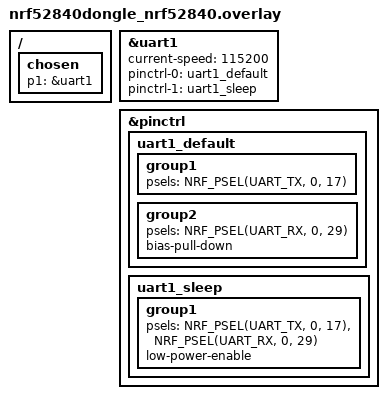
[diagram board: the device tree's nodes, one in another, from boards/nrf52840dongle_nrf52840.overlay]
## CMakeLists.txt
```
# SPDX-License-Identifier: Apache-2.0

cmake_minimum_required(VERSION 3.20.0)

find_package(Zephyr REQUIRED HINTS $ENV{ZEPHYR_BASE})
project(blep1)

SET(CMAKE_C_FLAGS "-O0")
SET(CMAKE_CPP_FLAGS "-O0")
set(CMAKE_BUILD_TYPE Debug)

FILE(GLOB app_sources src/*.c)
target_sources(app PRIVATE
  ${app_sources}
  )
```

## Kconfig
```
mainmenu "Blep1 application"

config BLEP1_SIM_DATA_ENABLED
  bool "Create some simulated data"
  default y

choice BLEP1_DATA_SOURCE
  bool "Choice of data source"
  default BLEP1_UART_DATA_SOURCE

config BLEP1_UART_DATA_SOURCE
  bool "Read data from UART"
  depends on BLEP1_SERIAL

config BLEP1_SIM_DATA_SOURCE
  bool "Read data directly from simulator"
endchoice

config BLEP1_SERIAL
  bool "Receive data from UART"
  default y

config BLEP1_SIM_UART_OUT
  bool "Send dummy data over tx line"
  default y
  depends on BLEP1_UART_DATA_SOURCE

config BLEP_IGNORE_UNKNOWN
  bool "Ignore unknown OBIS fields"
  default y

config BLEP_IGNORE_PARSING_ERRORS
  bool "Ignore fields with parsing errors"
  default y

choice BLEP_SOCKET_TYPE
  bool "Socket type"
  default BLEP_UDP

config BLEP_TCP
  bool "Use TCP socket"
  depends on NET_TCP

config BLEP_UDP
  bool "Use UDP socket"
  depends on NET_UDP
endchoice

config BLEP_HOSTNAME
  string "Hostname"
  default "blep-device"

config BLEP_SRP_INSTANCE_NAME
  string "SRP instance name"
  default "BLEP1 device"

config BLEP_LOG_TCP
  bool "Use TCP server for sending logs"
  default y

source "Kconfig.zephyr"
```

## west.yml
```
manifest:
  remotes:
    - name: zephyrproject-rtos
      url-base: https://github.com/zephyrproject-rtos
  projects:
    - name: zephyr
      remote: zephyrproject-rtos
      revision: v3.3.0
      import:
        path-prefix: external-code
```

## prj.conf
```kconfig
CONFIG_PIPES=y

CONFIG_BLEP_TCP=y

# Generic networking options
CONFIG_NETWORKING=y
CONFIG_NET_UDP=y
CONFIG_NET_TCP=y
CONFIG_NET_IPV6=y
CONFIG_NET_IPV4=n
CONFIG_NET_SOCKETS=y
CONFIG_NET_SOCKETS_POSIX_NAMES=y
CONFIG_POSIX_MAX_FDS=6
CONFIG_NET_CONNECTION_MANAGER=y

# Logging
CONFIG_LOG_MODE_DEFERRED=y
CONFIG_LOG_BUFFER_SIZE=4096
CONFIG_LOG_RUNTIME_FILTERING=y
CONFIG_LOG_FUNC_NAME_PREFIX_WRN=n
CONFIG_LOG_FUNC_NAME_PREFIX_INF=n
CONFIG_LOG_FUNC_NAME_PREFIX_ERR=n
CONFIG_LOG_FUNC_NAME_PREFIX_DBG=n

#CONFIG_FPU_SHARING=y

#CONFIG_BT_DEBUG_HCI_CORE=y

CONFIG_MODBUS=y
CONFIG_MODBUS_ROLE_SERVER=y
CONFIG_MODBUS_RAW_ADU=y
CONFIG_MODBUS_NUMOF_RAW_ADU=1
```

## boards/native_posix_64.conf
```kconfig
CONFIG_OPENP1_SERIAL=n

CONFIG_OPENP1_SIM_DATA_ENABLED=y
CONFIG_OPENP1_SIM_DATA_SOURCE=y

CONFIG_OPENP1_UART_DATA_SOURCE=n
CONFIG_OPENP1_SIM_UART_OUT=n

CONFIG_OPENP1_IGNORE_UNKNOWN=y
CONFIG_OPENP1_IGNORE_PARSING_ERRORS=n

CONFIG_SERIAL=n
CONFIG_UART_CONSOLE=n

CONFIG_NET_BUF=y

# Logging
CONFIG_NET_LOG=y
CONFIG_LOG=y
CONFIG_NET_STATISTICS=y
CONFIG_PRINTK=y

# Generic networking options
CONFIG_NETWORKING=y
CONFIG_NET_UDP=y
CONFIG_NET_IPV6=y
CONFIG_NET_SOCKETS=y
CONFIG_NET_SOCKETS_POSIX_NAMES=y
CONFIG_POSIX_MAX_FDS=6
CONFIG_NET_CONNECTION_MANAGER=y

# Network shell
CONFIG_SHELL=y
CONFIG_NATIVE_UART_0_ON_STDINOUT=y
CONFIG_NET_SHELL=y
CONFIG_NET_TCP=y

CONFIG_NET_CONFIG_SETTINGS=y

CONFIG_NET_CONFIG_MY_IPV6_ADDR="2001:db8:100::1"
CONFIG_NET_CONFIG_PEER_IPV6_ADDR="2001:db8:100::2"
CONFIG_ETH_NATIVE_POSIX_RANDOM_MAC=n
CONFIG_ETH_NATIVE_POSIX_MAC_ADDR="00:00:5e:00:53:64"
CONFIG_ETH_NATIVE_POSIX_STARTUP_AUTOMATIC=y
CONFIG_ETH_NATIVE_POSIX_SETUP_SCRIPT="./posix_net_setup.sh"
CONFIG_ETH_NATIVE_POSIX_DRV_NAME="zeth.1"
```

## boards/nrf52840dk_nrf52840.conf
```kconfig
CONFIG_SERIAL=y
CONFIG_UART_INTERRUPT_DRIVEN=y

CONFIG_NRFX_UARTE1=y
CONFIG_NFCT_PINS_AS_GPIOS=y

CONFIG_FPU=y

CONFIG_OPENP1_HOSTNAME="blep-dk"

# Kernel options
CONFIG_ENTROPY_GENERATOR=y
CONFIG_TEST_RANDOM_GENERATOR=y
CONFIG_INIT_STACKS=y

# Logging
CONFIG_NET_LOG=y
CONFIG_LOG=y
CONFIG_NET_STATISTICS=y
CONFIG_PRINTK=y

# Network buffers
CONFIG_NET_PKT_RX_COUNT=16
CONFIG_NET_PKT_TX_COUNT=16
CONFIG_NET_BUF_RX_COUNT=64
CONFIG_NET_BUF_TX_COUNT=64
CONFIG_NET_CONTEXT_NET_PKT_POOL=y

# IP address options
CONFIG_NET_IF_UNICAST_IPV6_ADDR_COUNT=6
CONFIG_NET_IF_MCAST_IPV6_ADDR_COUNT=4
CONFIG_NET_MAX_CONTEXTS=10

# Network shell
CONFIG_NET_SHELL=y
CONFIG_SHELL=y

# Network application options and configuration
CONFIG_NET_CONFIG_SETTINGS=y
CONFIG_NET_CONFIG_NEED_IPV6=y
#CONFIG_NET_CONFIG_MY_IPV6_ADDR="2001:db8::1"
#CONFIG_NET_CONFIG_PEER_IPV6_ADDR="2001:db8::2"

# How many client can connect to echo-server simultaneously

# These will break openthread! https://github.com/zephyrproject-rtos/zephyr/issues/34597
CONFIG_NET_IPV6_NBR_CACHE=n
CONFIG_NET_IPV6_MLD=n


CONFIG_SYSTEM_WORKQUEUE_STACK_SIZE=4096

# Enable OpenThread shell
CONFIG_OPENTHREAD_SHELL=y
CONFIG_SHELL_STACK_SIZE=3072

CONFIG_NET_L2_OPENTHREAD=y
#CONFIG_NET_IPV6_LOG_LEVEL_DBG=y

#CONFIG_OPENTHREAD_DEBUG=y
#CONFIG_OPENTHREAD_L2_DEBUG=y
#CONFIG_OPENTHREAD_L2_LOG_LEVEL_INF=y
#CONFIG_OPENTHREAD_LOG_LEVEL_INFO=y

CONFIG_OPENTHREAD_SLAAC=y
CONFIG_OPENTHREAD_JOINER=y
CONFIG_OPENTHREAD_JOINER_AUTOSTART=y
CONFIG_OPENTHREAD_JOINER_PSKD="ME0W4U"
CONFIG_OPENTHREAD_MANUAL_START=n
CONFIG_OPENTHREAD_PING_SENDER=y
CONFIG_OPENTHREAD_SRP_CLIENT=y
CONFIG_OPENTHREAD_DIAG=y
CONFIG_OPENTHREAD_RADIO_WORKQUEUE_STACK_SIZE=1024

# mbedTLS tweaks
CONFIG_MBEDTLS_SSL_MAX_CONTENT_LEN=768
CONFIG_MBEDTLS_HEAP_SIZE=16384

CONFIG_MAIN_STACK_SIZE=8192
CONFIG_PICOLIBC=y
```

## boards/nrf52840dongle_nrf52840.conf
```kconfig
CONFIG_SERIAL=y
CONFIG_UART_INTERRUPT_DRIVEN=y

CONFIG_BLEP1_SIM_DATA_ENABLED=n
CONFIG_BLEP1_UART_DATA_SOURCE=y
CONFIG_BLEP1_SIM_UART_OUT=n

CONFIG_NRFX_UARTE1=y
CONFIG_NFCT_PINS_AS_GPIOS=y

#CONFIG_POSIX_API=y
CONFIG_PICOLIBC=y
CONFIG_FPU=y

CONFIG_CONSOLE=y
CONFIG_UART_CONSOLE=y

# Kernel options
CONFIG_ENTROPY_GENERATOR=y
CONFIG_TEST_RANDOM_GENERATOR=y
CONFIG_INIT_STACKS=y

# Logging
CONFIG_NET_LOG=y
CONFIG_LOG=y
CONFIG_NET_STATISTICS=y
CONFIG_PRINTK=y

# Network buffers
CONFIG_NET_PKT_RX_COUNT=16
CONFIG_NET_PKT_TX_COUNT=16
CONFIG_NET_BUF_RX_COUNT=64
CONFIG_NET_BUF_TX_COUNT=64
CONFIG_NET_CONTEXT_NET_PKT_POOL=y

# IP address options
CONFIG_NET_IF_UNICAST_IPV6_ADDR_COUNT=6
CONFIG_NET_IF_MCAST_IPV6_ADDR_COUNT=4
CONFIG_NET_MAX_CONTEXTS=10

# Network shell
CONFIG_NET_SHELL=y
CONFIG_SHELL=y

# Network application options and configuration
CONFIG_NET_CONFIG_SETTINGS=y
CONFIG_NET_CONFIG_NEED_IPV6=y
#CONFIG_NET_CONFIG_MY_IPV6_ADDR="2001:db8::1"
#CONFIG_NET_CONFIG_PEER_IPV6_ADDR="2001:db8::2"

# How many client can connect to echo-server simultaneously

# These will break openthread! https://github.com/zephyrproject-rtos/zephyr/issues/34597
CONFIG_NET_IPV6_NBR_CACHE=n
CONFIG_NET_IPV6_MLD=n


CONFIG_SYSTEM_WORKQUEUE_STACK_SIZE=4096

# Enable OpenThread shell
CONFIG_OPENTHREAD_SHELL=y
CONFIG_SHELL_STACK_SIZE=3072

CONFIG_NET_L2_OPENTHREAD=y
#CONFIG_NET_IPV6_LOG_LEVEL_DBG=y

#CONFIG_OPENTHREAD_DEBUG=y
#CONFIG_OPENTHREAD_L2_DEBUG=y
#CONFIG_OPENTHREAD_L2_LOG_LEVEL_INF=y
#CONFIG_OPENTHREAD_LOG_LEVEL_INFO=y

CONFIG_OPENTHREAD_SLAAC=y
CONFIG_OPENTHREAD_JOINER=y
CONFIG_OPENTHREAD_JOINER_AUTOSTART=y
CONFIG_OPENTHREAD_JOINER_PSKD="ME0W4U"
CONFIG_OPENTHREAD_MANUAL_START=n
CONFIG_OPENTHREAD_PING_SENDER=y
CONFIG_OPENTHREAD_SRP_CLIENT=y
CONFIG_OPENTHREAD_DIAG=y
CONFIG_OPENTHREAD_RADIO_WORKQUEUE_STACK_SIZE=1024

# mbedTLS tweaks
CONFIG_MBEDTLS_SSL_MAX_CONTENT_LEN=768
CONFIG_MBEDTLS_HEAP_SIZE=16384

CONFIG_MAIN_STACK_SIZE=8192
CONFIG_PICOLIBC=y
```

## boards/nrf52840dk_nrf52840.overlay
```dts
/ {
	chosen {
		p1 = &uart1;
	};
};

&uart1 {
	status = "okay";
	current-speed = <115200>;
	pinctrl-0 = <&uart1_default>;
	pinctrl-1 = <&uart1_sleep>;
	pinctrl-names = "default", "sleep";
};

/*
&pinctrl {
	uart1_default: uart1_default {
		group1 {
			psels = <NRF_PSEL(UART_TX, 1, 10)>;
		};
		group2 {
			psels =	<NRF_PSEL(UART_RX, 0, 10)>;
			bias-pull-up;
		};
	};

	uart1_sleep: uart1_sleep {
		group1 {
			psels = <NRF_PSEL(UART_TX, 1, 10)>,
			      	<NRF_PSEL(UART_RX, 0, 10)>;
			low-power-enable;
		};
	};
};
*/
```

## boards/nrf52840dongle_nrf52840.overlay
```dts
/ {
	chosen {
		p1 = &uart1;
	};
};

&uart1 {
	status = "okay";
	current-speed = <115200>;
	pinctrl-0 = <&uart1_default>;
	pinctrl-1 = <&uart1_sleep>;
	pinctrl-names = "default", "sleep";
};

&pinctrl {
	uart1_default: uart1_default {
		group1 {
			psels = <NRF_PSEL(UART_TX, 0, 17)>;
		};
		group2 {
			psels =	<NRF_PSEL(UART_RX, 0, 29)>;
			bias-pull-down;
		};
	};

	uart1_sleep: uart1_sleep {
		group1 {
			psels = <NRF_PSEL(UART_TX, 0, 17)>,
			      	<NRF_PSEL(UART_RX, 0, 29)>;
			low-power-enable;
		};
	};
};
```

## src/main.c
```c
#include "lib/openp1.h"
#include "lib/parser.h"
#include "lib/telegram.h"
#include "lib/value_store.h"

#include "uart_p1.h"
#include "framer_task.h"
#include "parser_task.h"
#include "handler_task.h"
#include "modbus.h"
#include "tcp_log.h"

#include <zephyr/kernel.h>
#include <zephyr/logging/log.h>
#include <zephyr/net/openthread.h>
#include <openthread/srp_client.h>
#include <openthread/instance.h>

K_PIPE_DEFINE(rx_pipe, 4096, 4);
K_PIPE_DEFINE(tx_pipe, 4096, 4);
K_FIFO_DEFINE(telegram_frame_fifo);
K_MSGQ_DEFINE(telegram_queue, sizeof(telegram_message), 1, 4); 

LOG_MODULE_REGISTER(main, LOG_LEVEL_DBG);

const char HOSTNAME[] = CONFIG_OPENP1_HOSTNAME; 

struct value_store value_store;

void update_data_store(struct data_item *data_item) {
	value_store_update(&value_store, data_item);
}

#if CONFIG_OPENTHREAD
//typedef void (*otSrpClientAutoStartCallback)(const otSockAddr *aServerSockAddr, void *aContext);
void on_ot_srp_client_autostart_cb(const otSockAddr *aServerSockAddr, void *aContext) {
	uint8_t buf[INET6_ADDRSTRLEN];
	otIp6AddressToString(&aServerSockAddr->mAddress, buf, INET6_ADDRSTRLEN);
	LOG_INF("SRP autostart callback. Server: %s", buf);
}

const char INSTANCE_NAME[] = CONFIG_OPENP1_SRP_INSTANCE_NAME;
#if CONFIG_OPENP1_UDP
const char SERVICE_LABEL[] = "_blep1-modbus._udp";
#elif CONFIG_OPENP1_TCP
const char SERVICE_LABEL[] = "_blep1-modbus._tcp";
#else
const char SERVICE_LABEL[] = "_blep1-unknown._unknown";
#endif
struct otSrpClientService srp_client_service = {0};

static int service_registration() {
	struct otInstance *otInstance = openthread_get_default_instance();
	if (otInstance == NULL) {
		LOG_ERR("Openthread instance not available");
		return -1;
	}
	int ret = otSrpClientEnableAutoHostAddress(otInstance);
	if (ret != OT_ERROR_NONE) {
		LOG_ERR("Could not set auto host name address, error: %d", ret);
		return -1;
	}
	ret = otSrpClientSetHostName(otInstance, HOSTNAME);
	if (ret != OT_ERROR_NONE) {
		LOG_ERR("Could not set host name address, error: %d", ret);
		return -1;
	}
	srp_client_service.mInstanceName = INSTANCE_NAME;
	srp_client_service.mName = SERVICE_LABEL;
	srp_client_service.mPort = 502;

	ret = otSrpClientAddService(otInstance, &srp_client_service);
	if (ret != OT_ERROR_NONE) {
		LOG_ERR("Could not set service, error: %d", ret);
		return -1;
	}
	otSrpClientEnableAutoStartMode(otInstance, &on_ot_srp_client_autostart_cb, NULL);
	LOG_INF("Service discovery setup done");

	return 0;
}
#else
static int service_registration() { 
	LOG_INF("No service registration configured");
	return 0;
}

#endif


void main(void) {
	int err;
	LOG_INF("Starting..");

#if CONFIG_OPENP1_SERIAL
	err = uart_p1_init(&rx_pipe, &tx_pipe);
	if (err < 0) {
		LOG_ERR("Could not init uart (err %d)", err);
		return;
	}
#endif

	err = framer_task_init(&rx_pipe, &telegram_frame_fifo);
	if (err < 0) {
		LOG_ERR("Could not init parser task (err %d)", err);
		return;
	}

	err = parser_task_init(&telegram_frame_fifo, &telegram_queue);
	if (err < 0) {
		LOG_ERR("Could not init parser task (err %d)", err);
		return;
	}

	err = handler_task_init(&telegram_queue, &update_data_store);
	if (err < 0) {
		LOG_ERR("Could not init handler task (err %d)", err);
		return;
	}

	err = modbus_init(&value_store);
	if (err < 0) {
		LOG_ERR("Could not initalize Modbus server");
		return;
	}

#if CONFIG_OPENP1_LOG_TCP
	err = tcp_log_server_start();
	if (err < 0) {
		LOG_ERR("Could not initalize tcp log server");
		return;
	}
#endif

	err = service_registration();
	if (err < 0) {
		LOG_ERR("Could not start service registration");
		return;
	}

	LOG_INF("Up and running..");

	while (true) {
		k_sleep(K_SECONDS(1));
	}
}
```

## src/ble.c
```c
#include <zephyr/kernel.h>
#include <zephyr/logging/log.h>

#include <zephyr/bluetooth/bluetooth.h>
#include <zephyr/bluetooth/hci.h>
#include <zephyr/bluetooth/conn.h>
#include <zephyr/bluetooth/uuid.h>
#include <zephyr/bluetooth/gatt.h>

#include "ble.h"
#include "nus_log.h"

#include "lib/ble_definitions.h"
#include "lib/blep1.h"
#include "lib/common.h"

#if 0
LOG_MODULE_REGISTER(ble, LOG_LEVEL_DBG);

static struct bt_uuid_16 CHRC_UUID = BT_UUID_INIT_16(BT_UUID_GATT_CHRC_VAL);
static struct bt_uuid_16 CUD_UUID = BT_UUID_INIT_16(BT_UUID_GATT_CUD_VAL);
static struct bt_uuid_16 CPF_UUID = BT_UUID_INIT_16(BT_UUID_GATT_CPF_VAL);
static struct bt_uuid_16 CCC_UUID = BT_UUID_INIT_16(BT_UUID_GATT_CCC_VAL);

static ssize_t read_value(struct bt_conn *conn, const struct bt_gatt_attr *attr,
      void *buf, uint16_t len, uint16_t offset)
{
  struct user_data *user_data = attr->user_data;

  struct data_item data_item = {user_data->item, user_data->value };
  uint16_t size = data_item_size(&data_item);

//  LOG_DBG("Reading item: %d %d", user_data->item, user_data->value);

  return bt_gatt_attr_read(conn, attr, buf, len, offset, &user_data->value, size);
}

#define MAX_ATTRIBUTES 512

int ble_service_add_attributes(struct ble_service *ble_service, struct bt_gatt_attr *attributes, int count) {
	struct bt_gatt_attr *service_attributes = ble_service->gatt_service.attrs;
	size_t *index = &(ble_service->gatt_service.attr_count);

	for (int i = 0 ; i < count ; i++) {
		if (*index >= MAX_ATTRIBUTES) {
			LOG_ERR("Max attributes reached: %d", *index);
			return -1;
		}
		// Copy..
		service_attributes[*index] = attributes[i];
		*index += 1;
	}
	return 0;
}

int ble_service_update_item(struct ble_service *service, struct data_item *data_item) {
	int ret;
	struct user_data *data = &service->user_data[data_item->item];
	data->value = data_item->value;
	data->last_updated = 1;
	ret = bt_gatt_notify(NULL, data->attr, &data->value, data_item_size(data_item));
	if (ret < 0) {
		// This is normal when not connected..
		return -1;
	}
	return 0;
}

const struct bt_gatt_attr primary_service = BT_GATT_PRIMARY_SERVICE(&blep1_uuid);

int ble_service_add_primary_service(struct ble_service *service) {

	struct bt_gatt_attr attributes[] = { 
		primary_service
	};
	int ret = ble_service_add_attributes(service, attributes, ARRAY_SIZE(attributes));
	if (ret < 0) {
		LOG_ERR("Could not add primary service attribute(s)");
		return -1;
	}
	return 0;
}

int ble_service_add_item_attributes(struct ble_service * service) {
	for (int item = 0; item < _ITEM_COUNT; item++) {
		const struct gatt_ch *ch = &gatt_ch_table[item];
		struct bt_gatt_attr attributes[] = {
			BT_GATT_ATTRIBUTE(&CHRC_UUID.uuid, BT_GATT_PERM_READ, bt_gatt_attr_read_chrc, NULL, &service->chrc[item]),
			BT_GATT_ATTRIBUTE(&ch->uuid->uuid, BT_GATT_PERM_READ, read_value, NULL, &service->user_data[item]),
			BT_GATT_ATTRIBUTE(&CUD_UUID.uuid, BT_GATT_PERM_READ, bt_gatt_attr_read_cud, NULL, ch->description),
			BT_GATT_ATTRIBUTE(&CPF_UUID.uuid, BT_GATT_PERM_READ, bt_gatt_attr_read_cpf, NULL, ch->cpf), 
			BT_GATT_ATTRIBUTE(&CCC_UUID.uuid, BT_GATT_PERM_READ | BT_GATT_PERM_WRITE, 
				bt_gatt_attr_read_ccc, bt_gatt_attr_write_ccc, &service->ccc[item])
		};
		int ret = ble_service_add_attributes(service, attributes, ARRAY_SIZE(attributes));
		if (ret < 0) {
			LOG_ERR("Could not add item attribute: %d", item);
			return -1;
		}
		// Add a self reference for notficationas
		// Assumes the value attribute is third from bottom in list above
		struct bt_gatt_attr *value_attr = &service->gatt_service.attrs[service->gatt_service.attr_count - 4];
		service->user_data[item] = (struct user_data) { 
			.item = ch->item, 
			.last_updated = 0, 
			.attr = value_attr, 
		};
	}
	return 0;
}

void ble_service_init_chrc(struct ble_service *service) {
	for(int i = 0 ; i < ARRAY_SIZE(service->chrc); i++) {
		service->chrc[i] = (struct bt_gatt_chrc) { 
			.uuid = &(gatt_ch_table[i].uuid->uuid), 
			.value_handle = 0U, 
			.properties = BT_GATT_CHRC_READ  | BT_GATT_CHRC_NOTIFY,
		};
	}
}

void ble_service_init_ccc(struct ble_service *service) {
	for(int i = 0 ; i < ARRAY_SIZE(service->ccc); i++) {
		service->ccc[i] = (struct _bt_gatt_ccc) { 
			.cfg = {},
			.cfg_changed = NULL,
			.cfg_match = NULL,
			.cfg_write = NULL,
		};
	}
}

int ble_service_init(struct ble_service *service) {
	int err;
	// Allocate storage for max attributes, but uses less, saves some implementation time
	service->gatt_service.attrs = common_heap_alloc(sizeof(struct bt_gatt_attr) * MAX_ATTRIBUTES); 
	if (service->gatt_service.attrs == NULL) {
		LOG_ERR("Failed to allocate BLE service");
		return -1;
	}
	service->gatt_service.attr_count = 0;

	err = ble_service_add_primary_service(service);
	if (err < 0) {
		LOG_ERR("Failed to add item attributes");
		return -1;
	}

	ble_service_init_chrc(service);
	ble_service_init_ccc(service);

	err = ble_service_add_item_attributes(service);
	if (err < 0) {
		LOG_ERR("Failed to add item attributes");
		return -1;
	}

	LOG_INF("Registering %d attributes", service->gatt_service.attr_count);

	err = bt_gatt_service_register(&service->gatt_service);
	if (err < 0) {
		LOG_ERR("Failed to register service");
		return -1;
	}

	LOG_INF("Registering nus_log service");
	err = bt_gatt_service_register(&nus_log_service);


	return 0;
}

void ble_service_shutdown(struct ble_service *service) {
}

static void connected(struct bt_conn *conn, uint8_t err) {
	if (err) {
		printk("Connection failed (err 0x%02x)\n", err);
		return;
	}

	LOG_INF("Connected. MTU size: %d\n", bt_gatt_get_mtu(conn));
	struct bt_conn_info info;

  	struct bt_conn_le_tx_power tx_power;

	err = bt_conn_le_get_tx_power_level(conn, &tx_power);
  	if (err) {
    	LOG_ERR("Failed to get connection tx power level (err %d)\n", err);
  	} else {
		LOG_INF("Connected, phy: %d, tx power: %d, max tx power: %d", 
			tx_power.phy, tx_power.current_level, tx_power.max_level);
	}
}

static void disconnected(struct bt_conn *conn, uint8_t reason)
{
	printk("Disconnected (reason 0x%02x)\n", reason);
}

BT_CONN_CB_DEFINE(conn_callbacks) = {
	.connected = connected,
	.disconnected = disconnected,
};

static void auth_cancel(struct bt_conn *conn)
{
	char addr[BT_ADDR_LE_STR_LEN];

	bt_addr_le_to_str(bt_conn_get_dst(conn), addr, sizeof(addr));

	printk("Pairing cancelled: %s\n", addr);
}

static struct bt_conn_auth_cb auth_cb_display = {
	.cancel = auth_cancel,
};

//TODO check
static const struct bt_data ad[] = {
	BT_DATA_BYTES(BT_DATA_FLAGS, (BT_LE_AD_GENERAL | BT_LE_AD_NO_BREDR)),
	BT_DATA_BYTES(BT_DATA_UUID128_ALL, BT_UUID_BLEP1_SERVICE_VAL),
};

void bt_ready(void)
{
	int err;

	LOG_INF("Bluetooth initialized");

	err = bt_le_adv_start(BT_LE_ADV_CONN_NAME, ad, ARRAY_SIZE(ad), NULL, 0);
	
	
	if (err) {
		printk("Advertising failed to start (err %d)\n", err);
		return;
	}

	LOG_INF("Advertising successfully started");

	bt_conn_auth_cb_register(&auth_cb_display);
}
#endif
```

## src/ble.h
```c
#ifndef BLE_HEADER_H
#define BLE_HEADER_H

#include <zephyr/bluetooth/gatt.h>

#include "lib/telegram.h"

struct user_data {
	int item;
	int last_updated;
	union data_value value;
	struct bt_gatt_attr *attr;
};

struct ble_service {
	struct bt_gatt_service gatt_service;
	struct user_data user_data[_ITEM_COUNT];
    struct bt_gatt_chrc chrc[_ITEM_COUNT];
	struct _bt_gatt_ccc ccc[_ITEM_COUNT]; // Tricky to not use internal for dynamic db
};

void bt_ready(void);

int ble_service_init(struct ble_service *service);
void ble_service_shutdown(struct ble_service *service);
int ble_service_update_item(struct ble_service *service, struct data_item *data_item); 

#endif /* BLE_HEADER_H */
```

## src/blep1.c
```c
#include "blep1.h"

#include <zephyr/bluetooth/uuid.h>
#include <zephyr/bluetooth/gatt.h>


const struct data_definition data_definition_table[] = {
    { METER_ACTIVE_ENERGY_IN,   "1-0:1.8.0", DOUBLE_LONG_UNSIGNED_8_3, "kWh" },
    { METER_ACTIVE_ENERGY_OUT,  "1-0:2.8.0", DOUBLE_LONG_UNSIGNED_8_3, "kWh" },
    { ACTIVE_ENERGY_IN,         "1-0:1.7.0", DOUBLE_LONG_UNSIGNED_4_3, "kW"  },
    { ACTIVE_ENERGY_OUT,        "1-0:2.7.0", DOUBLE_LONG_UNSIGNED_4_3, "kW"  },
};
```

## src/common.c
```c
#include "common.h"

#include <zephyr/kernel.h>
#include <zephyr/logging/log.h>

#define ALIGNMENT 4

K_HEAP_DEFINE(common_heap, 32768);

void * common_heap_alloc(size_t bytes) {
    return k_heap_aligned_alloc(&common_heap, ALIGNMENT, bytes, K_NO_WAIT);
}

void common_heap_free(void *mem) {
    k_heap_free(&common_heap, mem);
}
```

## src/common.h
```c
#ifndef COMMON_HEADER_H
#define COMMON_HEADER_H

#include <stdlib.h>

void * common_heap_alloc(size_t bytes);
void common_heap_free(void *mem);

#endif /* COMMON_HEADER_H */
```

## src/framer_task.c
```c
#include <zephyr/logging/log.h>
#include <zephyr/net/buf.h>
#include <zephyr/kernel.h>
#include <sys/types.h>

#include "framer_task.h"
#include "lib/openp1.h"
#include "line_log.h"
#include "lib/telegram_framer.h"

#define READ_TIMEOUT_MS 200
#define MAX_TELEGRAM_SIZE 8192
#define TELEGRAM_BUF_POOL_SIZE 4

LOG_MODULE_REGISTER(framer_task, LOG_LEVEL_DBG);

K_SEM_DEFINE(start, 0, 1);

struct k_fifo *framed_telegram_queue;
struct k_pipe *input_pipe;

static struct telegram_framer *telegram_framer;

static struct line_log *line_log;

int framer_task_init(struct k_pipe *input, struct k_fifo *output) {
    input_pipe = input;
    framed_telegram_queue = output;

    line_log = line_log_init();
    if (line_log == NULL) {
        LOG_ERR("Failed to initialize line log");
        return -1;
    }
    telegram_framer = telegram_framer_init();
    if (telegram_framer == NULL) {
        LOG_ERR("Failed to initialize telegram framer");
        return -1;
    }
    k_sem_give(&start);
    return 0;
}

void framer_task(void *user_data) {
	uint8_t c;
    size_t bytes_read;
    k_sem_take(&start, K_FOREVER);
    LOG_INF("Telegram framer task started");
    while(true) {
        k_timeout_t timeout = telegram_framer_is_empty(telegram_framer) ? K_FOREVER : K_MSEC(READ_TIMEOUT_MS);
        int ret = k_pipe_get(input_pipe, &c, 1, &bytes_read, 1, timeout);
        if (ret < 0) {
            if (ret == -EINVAL) {
                LOG_ERR("Invalid argument, should not happen");
                return;
            }
            LOG_DBG("Discarding frame due to timeout");
            telegram_framer_reset(telegram_framer);
            line_log_reset(line_log);
        } else {
            line_log_push(line_log, c);
            struct net_buf *frame = telegram_framer_push(telegram_framer, c);
            if (frame != NULL) {
                net_buf_put(framed_telegram_queue, frame);
            }
	    }
    }
}

#define STACKSIZE 1024
#define PRIORITY 7

K_THREAD_DEFINE(framer_task_thread, STACKSIZE,
                framer_task, NULL, NULL, NULL,
                PRIORITY, 0, 0);
```

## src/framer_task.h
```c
#ifndef FRAMER_TASK_HEADER_H
#define FRAMER_TASK_HEADER_H

#include <zephyr/kernel.h>

int framer_task_init(struct k_pipe *input, struct k_fifo *output); 

#endif /* FRAMER_TASK_HEADER_H */
```

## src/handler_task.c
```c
#include <zephyr/kernel.h>

#include <zephyr/logging/log.h>
#include <sys/types.h>

#include "handler_task.h"

#include "lib/telegram.h"
#include "lib/openp1.h"

LOG_MODULE_REGISTER(handler_task, LOG_LEVEL_DBG);

#define STACKSIZE 1024
#define PRIORITY 7

K_SEM_DEFINE(handler_task_start, 0, 1);

static struct k_msgq *telegram_queue = NULL;
static update_value_store_fun update_value_store;

int handler_task_init(struct k_msgq *input, update_value_store_fun update_fun) {
    telegram_queue = input;
    update_value_store = update_fun;
    k_sem_give(&handler_task_start);
    return 0;
}

void handle_telegram(struct telegram *telegram) {
    int count = 0;
    struct data_item *data_item;
    struct telegram_data_iterator iter;
    telegram_item_iterator_init(telegram, &iter);
    while (NULL != (data_item = telegram_item_iterator_next(&iter))) {
        update_value_store(data_item);
        count++;
    }
    LOG_DBG("Value store updated with %d values.", count);
}

void handler_task(void *, void *, void *) {
    k_sem_take(&handler_task_start, K_FOREVER);
    LOG_INF("Telegram handler started");
    while (true) {
        telegram_message telegram_message;
        int ret = k_msgq_get(telegram_queue, &telegram_message, K_FOREVER);
        if (ret < 0) {
            LOG_ERR("Failed to receive message for some reason: %d", ret);
        } else {
            struct telegram *telegram = telegram_message.telegram;
            LOG_INF("Handler task received telegram");
            handle_telegram(telegram);
            telegram_free(telegram);
        }
    }
}

K_THREAD_DEFINE(handler_task_thread, STACKSIZE,
                handler_task, NULL, NULL, NULL,
                PRIORITY, 0, 0);
```

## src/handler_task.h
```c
#ifndef TELEGRAM_HANDLER_TASK_HEADER_H
#define TELEGRAM_HANDLER_TASK_HEADER_H

#include <zephyr/kernel.h>
#include "lib/telegram.h"

typedef void (*update_value_store_fun)(struct data_item *);

int handler_task_init(struct k_msgq *input, update_value_store_fun update_fun);

#endif /* PARSER_TASK_HEADER_H */
```

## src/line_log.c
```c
#include "line_log.h"
#include "lib/common.h"

#include "zephyr/logging/log.h"

LOG_MODULE_REGISTER(line_log, LOG_LEVEL_INF);

struct line_log * line_log_init() {
    struct line_log *log = common_heap_alloc(sizeof(struct line_log));
    if (log == NULL) {
        LOG_ERR("Failed to allocate line log");
        return NULL;
    }
    log->buf = common_heap_alloc(sizeof(char) * LINE_BUF_SIZE);
    if (log->buf == NULL) {
        LOG_ERR("Failed to allocate line log buffer");
    }
    log->pos = 0;
    return log;
}

void line_log_push(struct line_log *log, char c) {
    // Line logging for debugging
    int pos = log->pos;
    if (pos < LINE_BUF_SIZE) {
        log->buf[pos] = c;
        if (pos >= 2 && log->buf[pos - 1] == '\r' && c == '\n') {
            log->buf[pos-1] = '\0';
            LOG_INF("Recv: %s", log->buf);
            log->pos = 0;
        } else {
            log->pos = pos + 1;
        }
    } else {
        log->buf[LINE_BUF_SIZE - 1] = '\0';
        LOG_INF("Received too long line: %s..", log->buf);
        log->pos = 0;
    }
}

void line_log_reset(struct line_log *log) {
    log->pos = 0;
}

void line_log_free(struct line_log *log) {
    common_heap_free(log->buf);
    common_heap_free(log);
}
```

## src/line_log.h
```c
#ifndef LINE_LOG_HEADER_H
#define LINE_LOG_HEADER_H

#define LINE_BUF_SIZE 200

struct line_log {
    char *buf;
    int pos;
};

struct line_log * line_log_init();
void line_log_push(struct line_log *log, char c);
void line_log_reset(struct line_log *log);
void line_log_free(struct line_log *log);
 

#endif /* LINE_LOG_HEADER_H */
```

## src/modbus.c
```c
#include "modbus.h"
#include "lib/value_store.h"
#include "lib/blep1.h"
#include "udp.h"
#include "tcp.h"

#include <stdint.h>
#include <zephyr/modbus/modbus.h>

LOG_MODULE_REGISTER(modbus_server, LOG_LEVEL_DBG);

K_SEM_DEFINE(response_ready, 0, 1);
 
static int server_iface = -1;
static struct value_store *value_store;
static struct value_store value_store_snapshot;

static uint16_t read_word(struct data_item *data_item, uint16_t offset) {
	uint8_t buf[14]; // TODO max length should be defined somewhere.
    union data_value *value = &data_item->value;
	switch(data_definition_table[data_item->item].format) {
        case DATE_TIME_STRING:
			memcpy(buf, value->date_time, sizeof(value->date_time));
			break;
        case DOUBLE_LONG_UNSIGNED_8_3:
        case DOUBLE_LONG_UNSIGNED_4_3:
			sys_put_be32(value->double_long_unsigned, buf);
			break;
        case LONG_SIGNED_3_1:
        case LONG_UNSIGNED_3_1:
			// Shouldn't be needed, but let's keep it for consistency and to avoid any byte ordering bugs..
			sys_put_be16(value->long_unsigned, buf);
			break;
		default:
			LOG_ERR("BUG: Unhandled item");
			return 0;
	}
	return sys_get_be16(&buf[offset * 2]);
}

static int input_reg_rd(uint16_t addr, uint16_t *reg) {

	if (addr < 0x0800) {
		LOG_WRN("Trying to read non-implemented system registers");
		return -1;
	} 

	uint16_t value_addr = addr - DATA_BASE_ADDRESS;
	uint16_t item = value_addr / 32;
	uint16_t item_offset = value_addr % 32;

	struct value_store_read_result read_result = value_store_read(&value_store_snapshot, item);

	switch (read_result.status) {
		case INVALID:
			LOG_WRN("Read failure; invalid value");
			return -1; 
		case STALE:
			LOG_INF("Read failure; stale value");
			return -1;
		case OK:
			break;
		default:
			LOG_ERR("Read failure: unknown status");
			return -1;
	}

	struct data_item *data_item = &read_result.data.data;
	uint16_t size = data_item_size(data_item);

	if (item_offset > (size-1) /2 ) {
		LOG_ERR("Read failure: invalid offset");
		return -1;
	}

	uint16_t value = read_word(data_item, item_offset);
	LOG_INF("Modbus read input register, 0x%x = %d", addr, value);
	*reg = value;
	return 0;
}

static struct modbus_adu rx_adu;
static struct modbus_adu tx_adu;

static int respond(const int iface, const struct modbus_adu *adu, void *user_data) {
	LOG_INF("Server raw callback from interface %d", iface);
	if (SEND_BUFFER_SIZE < adu->length + MODBUS_MBAP_AND_FC_LENGTH) {
		// TODO set better exception type
		LOG_WRN("Response too large");
		modbus_raw_set_server_failure(&tx_adu);
		k_sem_give(&response_ready);
		return 0;
	}

	tx_adu.trans_id = adu->trans_id;
	tx_adu.proto_id = adu->proto_id;
	tx_adu.length = adu->length;
	tx_adu.unit_id = adu->unit_id;
	tx_adu.fc = adu->fc;
	memcpy(tx_adu.data, adu->data, adu->length);
	LOG_HEXDUMP_INF(tx_adu.data, tx_adu.length, "resp");
	k_sem_give(&response_ready);

	return 0;
}

static struct modbus_user_callbacks muc = {
    .input_reg_rd = input_reg_rd,
};

const static struct modbus_iface_param server_param = {
	.mode = MODBUS_MODE_RAW,
	.server = {
		.user_cb = &muc,
		.unit_id = 1,
	},
	.rawcb.raw_tx_cb = respond,
	.rawcb.user_data = NULL
};

static int send_reply(int socket) {
	uint8_t tx_buf[SEND_BUFFER_SIZE];
	modbus_raw_put_header(&tx_adu, tx_buf);
	// Size is checked earlier
	memcpy(&tx_buf[MODBUS_MBAP_AND_FC_LENGTH], tx_adu.data, tx_adu.length);

	#if CONFIG_BLEP_UDP
	return udp_server_send(tx_buf, MODBUS_MBAP_AND_FC_LENGTH + tx_adu.length);
	#elif CONFIG_BLEP_TCP
	return tcp_server_send(socket, tx_buf, MODBUS_MBAP_AND_FC_LENGTH + tx_adu.length);
	#else
	LOG_ERR("Unknown transport");
	return -1;
	#endif

}

#if CONFIG_BLEP_UDP
static int on_message_received(struct request *request) {
#else
static int on_message_received(struct tcp_request *request) {
#endif
	// Read header
	if (request->len < MODBUS_MBAP_AND_FC_LENGTH) {
		LOG_WRN("Received incomplete header");
		return -1;
	}

	modbus_raw_get_header(&rx_adu, request->recv_buffer);
	LOG_HEXDUMP_DBG(request->recv_buffer, sizeof(MODBUS_MBAP_AND_FC_LENGTH), "h:>");

	if (request->len < MODBUS_MBAP_AND_FC_LENGTH + rx_adu.length) {
		LOG_WRN("Received incomplete ADU");
		return -1;
	}

	memcpy(rx_adu.data, &request->recv_buffer[MODBUS_MBAP_AND_FC_LENGTH], rx_adu.length);

	// Take a snapshot of the value_store
	value_store_copy(value_store, &value_store_snapshot);

	if (modbus_raw_submit_rx(server_iface, &rx_adu)) {
		LOG_ERR("Failed to submit raw ADU");
		return -EIO;
	}

    // We trust our network to not DOS us with garbage
    // TODO: file a request for a dropped message callback
	if (k_sem_take(&response_ready, K_MSEC(500)) != 0) {
		LOG_ERR("Wait time for response expired");
		modbus_raw_set_server_failure(&tx_adu);
	}

	#if CONFIG_BLEP_UDP
	return send_reply(0);
	#else
	return send_reply(request->socket);
	#endif
}

#if CONFIG_BLEP_UDP
struct message_handler handler = {
	.on_message_recived_cb = on_message_received,
};
#elif CONFIG_BLEP_TCP
struct tcp_message_handler handler = {
	.on_message_recived_cb = on_message_received,
};
#endif


int modbus_init(struct value_store *store) {

	value_store = store;

	#if CONFIG_BLEP_UDP
    if (udp_server_init(&handler) < 0) {
        return -1;
    }
	#elif CONFIG_BLEP_TCP
	if (tcp_server_init(&handler) < 0) {
		return -1;
	}
	#else
	LOG_ERR("Unknown transport");
	return -1;
	#endif
    
	char iface_name[] = "RAW_0";
	server_iface = modbus_iface_get_by_name(iface_name);

	if (server_iface < 0) {
		LOG_ERR("Failed to get iface index for %s", iface_name);
		return -ENODEV;
	}

	return modbus_init_server(server_iface, server_param);
}
```
